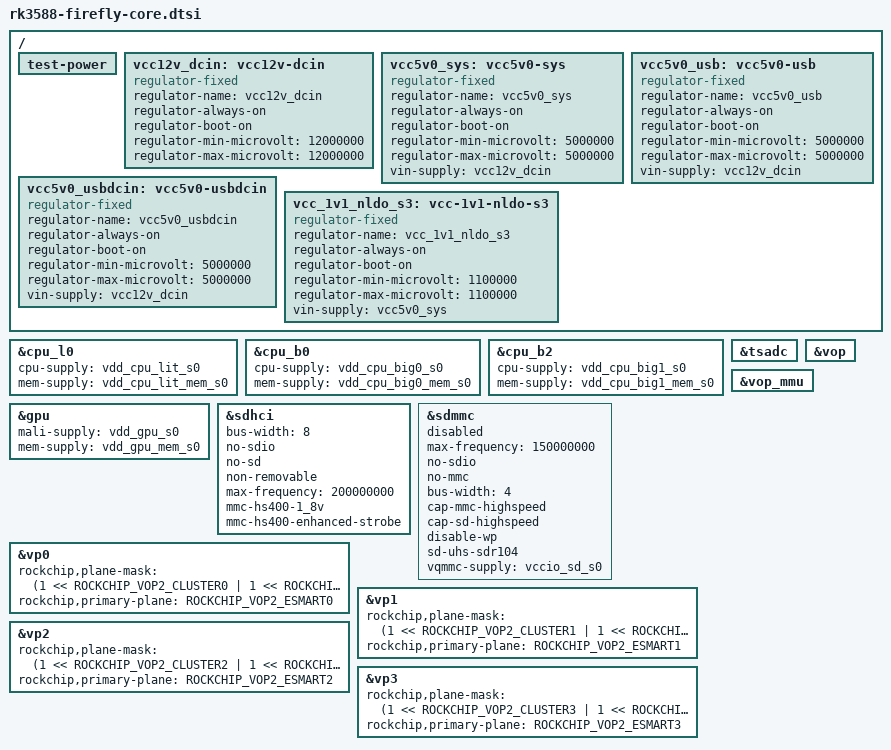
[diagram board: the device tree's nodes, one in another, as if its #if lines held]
// SPDX-License-Identifier: (GPL-2.0+ OR MIT)
/*
 * Copyright (c) 2021 Rockchip Electronics Co., Ltd.
 *
 */

#include "dt-bindings/usb/pd.h"
#ifdef rk3588
#include "rk3588.dtsi"
#else
#include "rk3588s-f.dtsi"
#endif
#include "rk3588-firefly-rk806-single.dtsi"
#include <dt-bindings/gpio/gpio.h>
#include <dt-bindings/pwm/pwm.h>
#include <dt-bindings/pinctrl/rockchip.h>
#include <dt-bindings/display/rockchip_vop.h>

/ {
	test-power {
		status = "okay";
	};

	vcc12v_dcin: vcc12v-dcin {
		compatible = "regulator-fixed";
		regulator-name = "vcc12v_dcin";
		regulator-always-on;
		regulator-boot-on;
		regulator-min-microvolt = <12000000>;
		regulator-max-microvolt = <12000000>;
	};

	vcc5v0_sys: vcc5v0-sys {
		compatible = "regulator-fixed";
		regulator-name = "vcc5v0_sys";
		regulator-always-on;
		regulator-boot-on;
		regulator-min-microvolt = <5000000>;
		regulator-max-microvolt = <5000000>;
		vin-supply = <&vcc12v_dcin>;
	};

	vcc5v0_usbdcin: vcc5v0-usbdcin {
		compatible = "regulator-fixed";
		regulator-name = "vcc5v0_usbdcin";
		regulator-always-on;
		regulator-boot-on;
		regulator-min-microvolt = <5000000>;
		regulator-max-microvolt = <5000000>;
		vin-supply = <&vcc12v_dcin>;
	};

	vcc5v0_usb: vcc5v0-usb {
		compatible = "regulator-fixed";
		regulator-name = "vcc5v0_usb";
		regulator-always-on;
		regulator-boot-on;
		regulator-min-microvolt = <5000000>;
		regulator-max-microvolt = <5000000>;
		vin-supply = <&vcc12v_dcin>;
	};

	vcc_1v1_nldo_s3: vcc-1v1-nldo-s3 {
		compatible = "regulator-fixed";
		regulator-name = "vcc_1v1_nldo_s3";
		regulator-always-on;
		regulator-boot-on;
		regulator-min-microvolt = <1100000>;
		regulator-max-microvolt = <1100000>;
		vin-supply = <&vcc5v0_sys>;
	};
};

&cpu_l0 {
	cpu-supply = <&vdd_cpu_lit_s0>;
	mem-supply = <&vdd_cpu_lit_mem_s0>;
};

&cpu_b0 {
	cpu-supply = <&vdd_cpu_big0_s0>;
	mem-supply = <&vdd_cpu_big0_mem_s0>;
};

&cpu_b2 {
	cpu-supply = <&vdd_cpu_big1_s0>;
	mem-supply = <&vdd_cpu_big1_mem_s0>;
};

&gpu {
	mali-supply = <&vdd_gpu_s0>;
	mem-supply = <&vdd_gpu_mem_s0>;
	status = "okay";
};

&sdhci {
	bus-width = <8>;
	no-sdio;
	no-sd;
	non-removable;
	max-frequency = <200000000>;
	mmc-hs400-1_8v;
	mmc-hs400-enhanced-strobe;
	status = "okay";
};

&sdmmc {
	max-frequency = <150000000>;
	no-sdio;
	no-mmc;
	bus-width = <4>;
	cap-mmc-highspeed;
	cap-sd-highspeed;
	disable-wp;
	sd-uhs-sdr104;
	vqmmc-supply = <&vccio_sd_s0>;
	status = "disabled";
};

&tsadc {
	status = "okay";
};

&vop {
	status = "okay";
};

&vop_mmu {
	status = "okay";
};

/* vp0 & vp1 splice for 8K output */
&vp0 {
	rockchip,plane-mask = <(1 << ROCKCHIP_VOP2_CLUSTER0 | 1 << ROCKCHIP_VOP2_ESMART0)>;
	rockchip,primary-plane = <ROCKCHIP_VOP2_ESMART0>;
};

&vp1 {
	rockchip,plane-mask = <(1 << ROCKCHIP_VOP2_CLUSTER1 | 1 << ROCKCHIP_VOP2_ESMART1)>;
	rockchip,primary-plane = <ROCKCHIP_VOP2_ESMART1>;
};

&vp2 {
	rockchip,plane-mask = <(1 << ROCKCHIP_VOP2_CLUSTER2 | 1 << ROCKCHIP_VOP2_ESMART2)>;
	rockchip,primary-plane = <ROCKCHIP_VOP2_ESMART2>;
};

&vp3 {
	rockchip,plane-mask = <(1 << ROCKCHIP_VOP2_CLUSTER3 | 1 << ROCKCHIP_VOP2_ESMART3)>;
	rockchip,primary-plane = <ROCKCHIP_VOP2_ESMART3>;
};
